# C2000_Code_Security_Module_Registers register map
Vendor: Texas Instruments
Peripheral module from a debugger description file (folder C2000).
Address unit: 16 bits
Registers are 16-bit, access not given, no defined reset value unless marked. A register's access mark holds for its fields unless they carry their own. Offsets are as the file gives them; lines under a group give offsets from that group; [hi:lo] are bit positions; {n}, {i} and the like mark numbered series; 'fields as' and 'values as' point back to an identical list; <NAME> marks a mode.

## CSM — Code Security Module
{0x0+i} KEY{i} (i=0..7) — CSM Key {i} Register
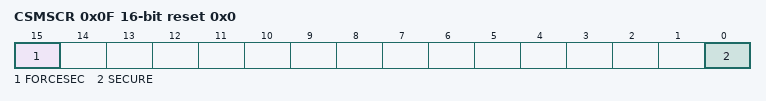
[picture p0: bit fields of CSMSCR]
0x0F CSMSCR rw reset 0x0
  [15] FORCESEC — Force Secure bit
  [0] SECURE — Secure bit
